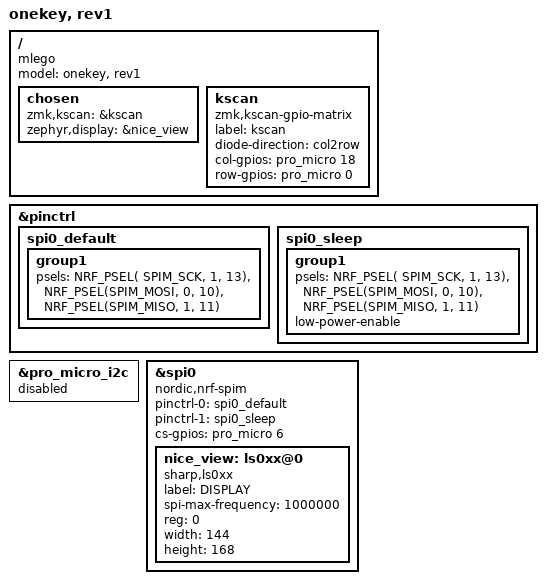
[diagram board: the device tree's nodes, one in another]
/*
 * Copyright (c) 2022-2023 alin m elena
 * SPDX-License-Identifier: MIT
 */

#include <dt-bindings/zmk/matrix_transform.h>

/ {
   model = "onekey, rev1";

   compatible = "mlego", "nice-nano-v2";

   chosen {
     zmk,kscan = &kscan;
     zephyr,display = &nice_view;
   };

   kscan: kscan {
     compatible = "zmk,kscan-gpio-matrix";
     label = "kscan";
     diode-direction = "col2row";
     col-gpios =  <&pro_micro 18 (GPIO_ACTIVE_HIGH | GPIO_PULL_DOWN)>
                 ;
     row-gpios =   <&pro_micro 0  (GPIO_ACTIVE_HIGH | GPIO_PULL_DOWN)>
                 ;
   };
};

&pinctrl {
    spi0_default: spi0_default {
        group1 {
            psels =   <NRF_PSEL( SPIM_SCK, 1, 13)> 
                    , <NRF_PSEL(SPIM_MOSI, 0, 10)>
                    , <NRF_PSEL(SPIM_MISO, 1, 11)>
                    ;
        };
    };
    spi0_sleep: spi0_sleep {
        group1 {
            psels =   <NRF_PSEL( SPIM_SCK, 1, 13)> 
                    , <NRF_PSEL(SPIM_MOSI, 0, 10)>
                    , <NRF_PSEL(SPIM_MISO, 1, 11)>
                    ;
            low-power-enable;
        };
    };
};

&pro_micro_i2c {
    status = "disabled";
};

nice_view_spi: &spi0 {
  status = "okay";
  compatible = "nordic,nrf-spim";
  pinctrl-0 = <&spi0_default>;
  pinctrl-1 = <&spi0_sleep>;
  pinctrl-names = "default", "sleep";

  cs-gpios =  <&pro_micro 6 GPIO_ACTIVE_HIGH> 
             ;
  nice_view: ls0xx@0 {
    compatible = "sharp,ls0xx";
    status = "okay";
    label = "DISPLAY";
/*
    disp-en-gpios = <&pro_micro 9 GPIO_ACTIVE_LOW>;
*/
    spi-max-frequency = <1000000>;
    reg = <0>;
    width = <144>;
    height = <168>;
  };

};
